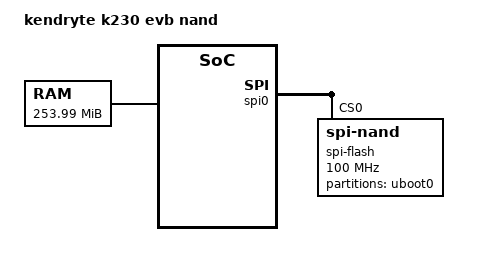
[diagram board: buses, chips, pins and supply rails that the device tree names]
/* Copyright (c) 2023, Canaan Bright Sight Co., Ltd
 *
 * Redistribution and use in source and binary forms, with or without
 * modification, are permitted provided that the following conditions are met:
 * 1. Redistributions of source code must retain the above copyright
 * notice, this list of conditions and the following disclaimer.
 * 2. Redistributions in binary form must reproduce the above copyright
 * notice, this list of conditions and the following disclaimer in the
 * documentation and/or other materials provided with the distribution.
 *
 * THIS SOFTWARE IS PROVIDED BY THE COPYRIGHT HOLDERS AND
 * CONTRIBUTORS "AS IS" AND ANY EXPRESS OR IMPLIED WARRANTIES,
 * INCLUDING, BUT NOT LIMITED TO, THE IMPLIED WARRANTIES OF
 * MERCHANTABILITY AND FITNESS FOR A PARTICULAR PURPOSE ARE
 * DISCLAIMED. IN NO EVENT SHALL THE COPYRIGHT HOLDER OR
 * CONTRIBUTORS BE LIABLE FOR ANY DIRECT, INDIRECT, INCIDENTAL,
 * SPECIAL, EXEMPLARY, OR CONSEQUENTIAL DAMAGES (INCLUDING,
 * BUT NOT LIMITED TO, PROCUREMENT OF SUBSTITUTE GOODS OR
 * SERVICES; LOSS OF USE, DATA, OR PROFITS; OR BUSINESS
 * INTERRUPTION) HOWEVER CAUSED AND ON ANY THEORY OF LIABILITY,
 * WHETHER IN CONTRACT, STRICT LIABILITY, OR TORT (INCLUDING
 * NEGLIGENCE OR OTHERWISE) ARISING IN ANY WAY OUT OF THE USE
 * OF THIS SOFTWARE, EVEN IF ADVISED OF THE POSSIBILITY OF SUCH DAMAGE.
 */
/dts-v1/;
#include "k230_evb.dtsi"

/ {
	model = "kendryte k230 evb nand";
	compatible = "kendryte,k230_evb_nand";

	memory@0 {
		device_type = "memory";
		reg = <
				0x0 0x8000000 0x0 0x7fff000  /*MEM_LINUX_SYS*/
				0x0 0x200000 0x0 0x7dff000  /*MEM_RTT_SYS*/
			  >;
	};
};

&spi0 {
	status = "okay";
	rx-sample-delay-ns = <5>;
	spi-flash@0 {
		compatible = "spi-nand";
		reg = <0>;
		spi-max-frequency = <100000000>;
		spi-tx-bus-width = <8>;
		spi-rx-bus-width = <8>;
		status = "okay";
		u-boot,dm-pre-reloc;
		partitions {
			compatible = "fixed-partitions";
			#address-cells = <1>;
			#size-cells = <1>;
			uboot@0 {
				label = "uboot0";
				reg = <0x00000000 0x0080000>;
			};
		};
	};
};
